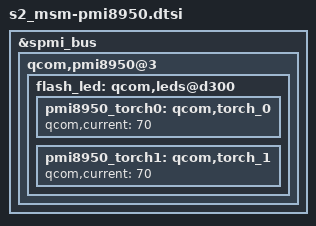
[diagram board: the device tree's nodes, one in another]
/* Copyright (c) 2015, The Linux Foundation. All rights reserved.
 *
 * This program is free software; you can redistribute it and/or modify
 * it under the terms of the GNU General Public License version 2 and
 * only version 2 as published by the Free Software Foundation.
 *
 * This program is distributed in the hope that it will be useful,
 * but WITHOUT ANY WARRANTY; without even the implied warranty of
 * MERCHANTABILITY or FITNESS FOR A PARTICULAR PURPOSE.  See the
 * GNU General Public License for more details.
 */

&spmi_bus {
	qcom,pmi8950@3 {
		flash_led: qcom,leds@d300 {

			pmi8950_torch0: qcom,torch_0 {
				/delete-property/ qcom,current;
				qcom,current = <70>;
			};

			pmi8950_torch1: qcom,torch_1 {
				/delete-property/ qcom,current;
				qcom,current = <70>;
			};
		};
	};
};
